# PIC16F15276 register map
File version: 1.0
Registers are 8-bit, read-write, reset 0x0 unless marked. A register's access mark holds for its fields unless they carry their own. Offsets are from the block's base; [hi:lo] are bit positions; {n}, {i} and the like mark numbered series.

## EUSART
Base 0x00800119
0x00 RC1REG — RC1REG, data address 0x119
  [7:0] RCREG
0x01 TX1REG — TX1REG, data address 0x11a
  [7:0] TXREG
0x02 SP1BRGL — SP1BRGL, data address 0x11b
  [7:0] SPBRGL
0x03 SP1BRGH — SP1BRGH, data address 0x11c
  [7:0] SPBRGH
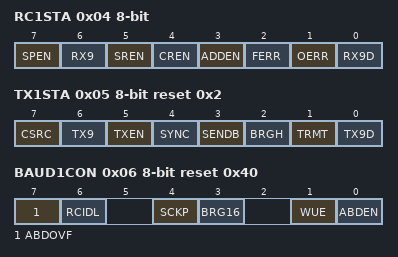
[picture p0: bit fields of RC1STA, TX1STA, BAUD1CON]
0x04 RC1STA (reset mask 0xFE) — RC1STA, data address 0x11d
  [7] SPEN, [6] RX9, [5] SREN, [4] CREN, [3] ADDEN, [2] FERR, [1] OERR, [0] RX9D
0x05 TX1STA reset 0x2 — TX1STA, data address 0x11e
  [7] CSRC, [6] TX9, [5] TXEN, [4] SYNC, [3] SENDB, [2] BRGH, [1] TRMT, [0] TX9D
0x06 BAUD1CON reset 0x40 — BAUD1CON, data address 0x11f
  [7] ABDOVF, [6] RCIDL, [4] SCKP, [3] BRG16, [1] WUE, [0] ABDEN

## INTERRUPTS — Interrupt flags and enables
Base 0x0080070C
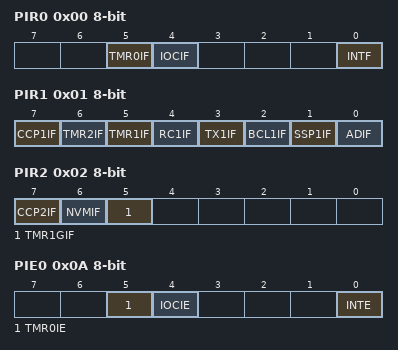
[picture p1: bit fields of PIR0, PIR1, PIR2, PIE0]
0x00 PIR0 — PIR0, data address 0x70c
  [5] TMR0IF, [4] IOCIF, [0] INTF
0x01 PIR1 — PIR1, data address 0x70d
  [7] CCP1IF, [6] TMR2IF, [5] TMR1IF, [4] RC1IF, [3] TX1IF, [2] BCL1IF, [1] SSP1IF, [0] ADIF
0x02 PIR2 — PIR2, data address 0x70e
  [7] CCP2IF, [6] NVMIF, [5] TMR1GIF
0x0A PIE0 — PIE0, data address 0x716
  [5] TMR0IE, [4] IOCIE, [0] INTE
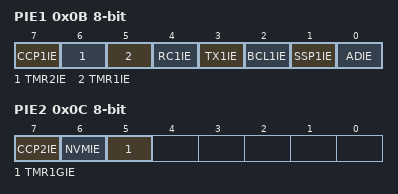
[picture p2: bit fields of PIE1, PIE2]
0x0B PIE1 — PIE1, data address 0x717
  [7] CCP1IE, [6] TMR2IE, [5] TMR1IE, [4] RC1IE, [3] TX1IE, [2] BCL1IE, [1] SSP1IE, [0] ADIE
0x0C PIE2 — PIE2, data address 0x718
  [7] CCP2IE, [6] NVMIE, [5] TMR1GIE

## MSSP — Synchronous serial port
Base 0x0080018C
0x00 SSP1BUF reset not defined — SSP1BUF, data address 0x18c
  [7:0] SSPBUF
0x01 SSP1ADD — SSP1ADD, data address 0x18d
  [7:0] SSPADD
0x02 SSP1MSK reset 0xFF — SSP1MSK, data address 0x18e
  [7:0] SSPMSK
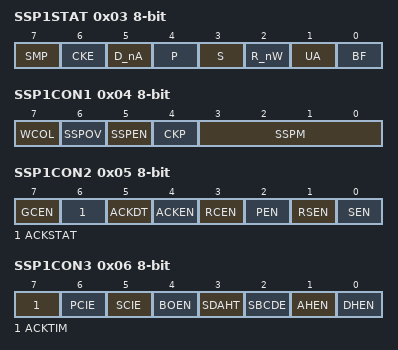
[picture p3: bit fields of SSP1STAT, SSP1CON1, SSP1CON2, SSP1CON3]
0x03 SSP1STAT — SSP1STAT, data address 0x18f
  [7] SMP, [6] CKE, [5] D_nA, [4] P, [3] S, [2] R_nW, [1] UA, [0] BF
0x04 SSP1CON1 — SSP1CON1, data address 0x190
  [7] WCOL, [6] SSPOV, [5] SSPEN, [4] CKP, [3:0] SSPM
0x05 SSP1CON2 — SSP1CON2, data address 0x191
  [7] GCEN, [6] ACKSTAT, [5] ACKDT, [4] ACKEN, [3] RCEN, [2] PEN, [1] RSEN, [0] SEN
0x06 SSP1CON3 — SSP1CON3, data address 0x192
  [7] ACKTIM, [6] PCIE, [5] SCIE, [4] BOEN, [3] SDAHT, [2] SBCDE, [1] AHEN, [0] DHEN
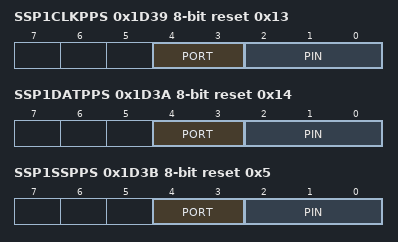
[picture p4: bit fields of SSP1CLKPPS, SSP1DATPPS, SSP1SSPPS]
0x1D39 SSP1CLKPPS reset 0x13 — SSP1CLKPPS, data address 0x1ec5
  [4:3] PORT, [2:0] PIN
0x1D3A SSP1DATPPS reset 0x14 — SSP1DATPPS, data address 0x1ec6
  [4:3] PORT, [2:0] PIN
0x1D3B SSP1SSPPS reset 0x5 — SSP1SSPPS, data address 0x1ec7
  [4:3] PORT, [2:0] PIN

## NVM — Flash and EEPROM access
Base 0x0080081A
0x00 NVMADRL — NVMADRL, data address 0x81a
0x01 NVMADRH reset 0x80 — NVMADRH, data address 0x81b
  [6:0] NVMADRH
0x02 NVMDATL — NVMDATL, data address 0x81c
0x03 NVMDATH — NVMDATH, data address 0x81d
  [5:0] NVMDATH
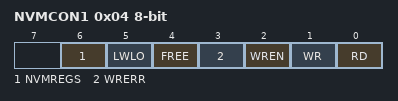
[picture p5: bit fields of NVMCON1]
0x04 NVMCON1 (reset mask 0x77) — NVMCON1, data address 0x81e
  [6] NVMREGS, [5] LWLO, [4] FREE, [3] WRERR, [2] WREN, [1] WR, [0] RD
0x05 NVMCON2 — NVMCON2, data address 0x81f

## OSCILLATOR
Base 0x0080088E
0x00 OSCCON reset not defined — OSCCON, data address 0x88e
  [5:4] COSC
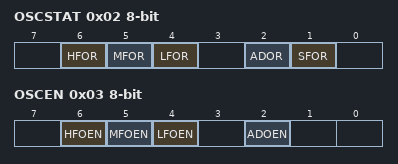
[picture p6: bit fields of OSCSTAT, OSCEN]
0x02 OSCSTAT reset not defined — OSCSTAT, data address 0x890
  [6] HFOR, [5] MFOR, [4] LFOR, [2] ADOR, [1] SFOR
0x03 OSCEN — OSCEN, data address 0x891
  [6] HFOEN, [5] MFOEN, [4] LFOEN, [2] ADOEN
0x04 OSCTUNE — OSCTUNE, data address 0x892
  [5:0] TUN
0x05 OSCFRQ reset not defined — OSCFRQ, data address 0x893
  [2:0] FRQ

## PORTA
Base 0x0080000C
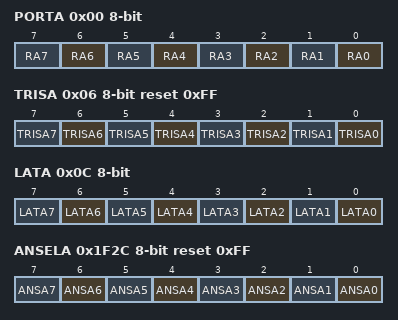
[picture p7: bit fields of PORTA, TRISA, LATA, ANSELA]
0x00 PORTA reset not defined — PORTA, data address 0x00c
  [n] RA{n} (n=0..7)
0x06 TRISA reset 0xFF — TRISA, data address 0x012
  [n] TRISA{n} (n=0..7)
0x0C LATA reset not defined — LATA, data address 0x018
  [n] LATA{n} (n=0..7)
0x1F2C ANSELA reset 0xFF — ANSELA, data address 0x1f38
  [n] ANSA{n} (n=0..7)
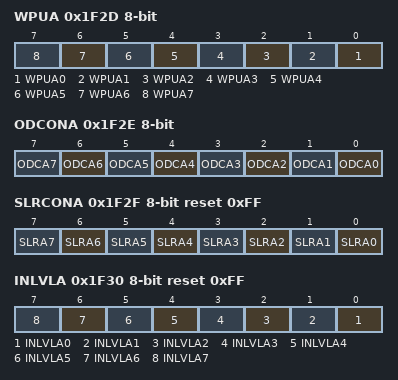
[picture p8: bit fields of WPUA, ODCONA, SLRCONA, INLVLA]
0x1F2D WPUA — WPUA, data address 0x1f39
  [n] WPUA{n} (n=0..7)
0x1F2E ODCONA — ODCONA, data address 0x1f3a
  [n] ODCA{n} (n=0..7)
0x1F2F SLRCONA reset 0xFF — SLRCONA, data address 0x1f3b
  [n] SLRA{n} (n=0..7)
0x1F30 INLVLA reset 0xFF — INLVLA, data address 0x1f3c
  [n] INLVLA{n} (n=0..7)
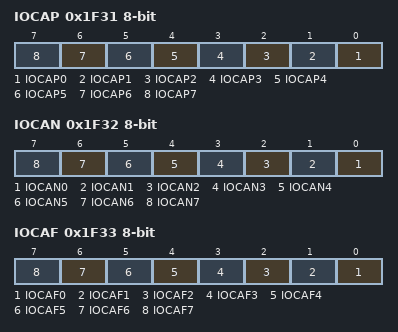
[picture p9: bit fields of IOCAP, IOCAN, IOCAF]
0x1F31 IOCAP — IOCAP, data address 0x1f3d
  [n] IOCAP{n} (n=0..7)
0x1F32 IOCAN — IOCAN, data address 0x1f3e
  [n] IOCAN{n} (n=0..7)
0x1F33 IOCAF — IOCAF, data address 0x1f3f
  [n] IOCAF{n} (n=0..7)
